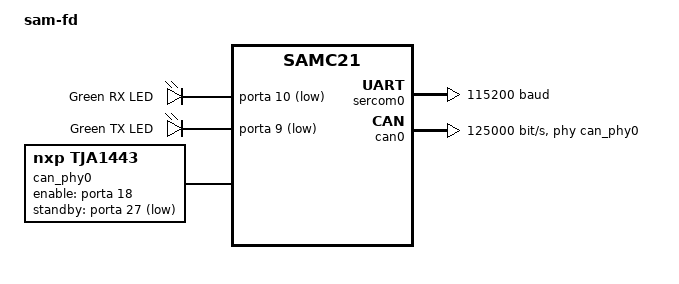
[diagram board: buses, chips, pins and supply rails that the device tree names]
/*
 * Copyright (c) 2021 Nordic Semiconductor ASA
 * Copyright (c) 2023 Leon Rinkel
 * SPDX-License-Identifier: Apache-2.0
 */

/dts-v1/;

#include <atmel/samc21.dtsi>
#include <atmel/samx2xx16.dtsi>
#include "sam_fd-pinctrl.dtsi"

/ {
	model = "sam-fd";
	compatible = "vendor,sam-fd";

	chosen {
		zephyr,console = &sercom0;
		zephyr,shell-uart = &sercom0;
		zephyr,sram = &sram0;
		zephyr,flash = &flash0;
		zephyr,canbus = &can0;
	};

	aliases {
		rx-led = &rx_led;
		tx-led = &tx_led;
	};

	leds {
		compatible = "gpio-leds";
		rx_led: led_0 {
			gpios = <&porta 10 GPIO_ACTIVE_LOW>;
			label = "Green RX LED";
		};
		tx_led: led_1 {
			gpios = <&porta 9 GPIO_ACTIVE_LOW>;
			label = "Green TX LED";
		};
	};

	can_phy0: can-phy0 {
		compatible = "nxp,tja1443", "can-transceiver-gpio";
		enable-gpios = <&porta 18 GPIO_ACTIVE_HIGH>;
		standby-gpios = <&porta 27 GPIO_ACTIVE_LOW>;
		max-bitrate = <5000000>;
		#phy-cells = <0>;
	};
};

&cpu0 {
	clock-frequency = <48000000>;
};

&sercom0 {
	status = "okay";
	compatible = "atmel,sam0-uart";
	current-speed = <115200>;
	rxpo = <1>;
	txpo = <1>;

	pinctrl-0 = <&sercom0_uart_default>;
	pinctrl-names = "default";
};

&flash0 {
	partitions {
		compatible = "fixed-partitions";
		#address-cells = <1>;
		#size-cells = <1>;

		storage_partition: partition@3c000 {
			label = "storage";
			reg = <0x0003c000 0x00004000>;
		};
	};
};

&can0 {
	pinctrl-0 = <&can0_default>;
	pinctrl-names = "default";
	phys = <&can_phy0>;
	bus-speed = <125000>;
	sample-point = <875>;
	bus-speed-data = <1000000>;
	sample-point-data = <875>;
	status = "okay";
};
